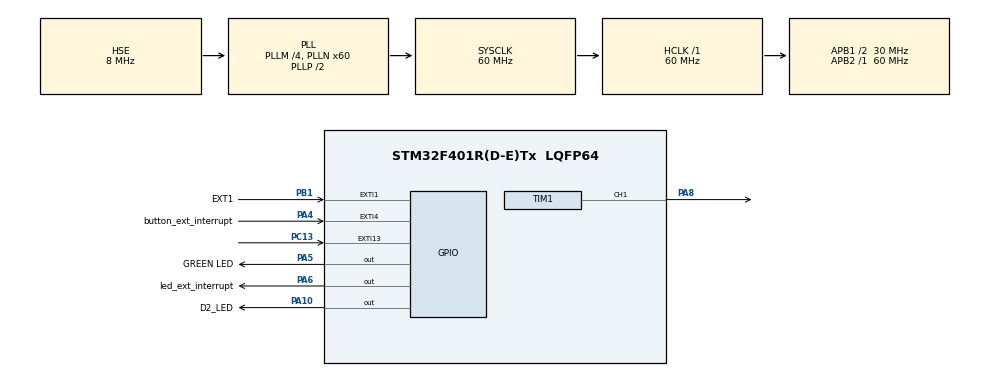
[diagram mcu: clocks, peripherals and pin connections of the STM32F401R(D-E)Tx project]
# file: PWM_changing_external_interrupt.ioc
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Mcu.Family=STM32F4
Mcu.Name=STM32F401R(D-E)Tx
Mcu.Package=LQFP64
NVIC.EXTI15_10_IRQn=true\:0\:0\:true\:false\:true\:true\:true\:true
NVIC.EXTI1_IRQn=true\:0\:0\:false\:false\:true\:true\:true\:true
NVIC.EXTI4_IRQn=true\:1\:0\:true\:false\:true\:true\:true\:true
NVIC.PriorityGroup=NVIC_PRIORITYGROUP_4
PA10.GPIO_Label=D2_LED
PA10.Signal=GPIO_Output
PA13.Mode=Serial_Wire
PA13.Signal=SYS_JTMS-SWDIO
PA14.Mode=Serial_Wire
PA14.Signal=SYS_JTCK-SWCLK
PA4.GPIO_Label=button_ext_interrupt
PA4.GPIO_ModeDefaultEXTI=GPIO_MODE_IT_FALLING
PA4.Signal=GPXTI4
PA5.GPIO_Label=GREEN LED
PA5.Signal=GPIO_Output
PA6.GPIO_Label=led_ext_interrupt
PA6.Signal=GPIO_Output
PA8.Signal=S_TIM1_CH1
PB1.GPIO_Label=EXT1
PB1.Signal=GPXTI1
PC13-ANTI_TAMP.Signal=GPXTI13
PH0\ -\ OSC_IN.Mode=HSE-External-Oscillator
PH0\ -\ OSC_IN.Signal=RCC_OSC_IN
PH1\ -\ OSC_OUT.Mode=HSE-External-Oscillator
PH1\ -\ OSC_OUT.Signal=RCC_OSC_OUT
ProjectManager.HeapSize=0x200
ProjectManager.StackSize=0x400
ProjectManager.TargetToolchain=STM32CubeIDE
RCC.48MHZClocksFreq_Value=30000000
RCC.AHBFreq_Value=60000000
RCC.APB1CLKDivider=RCC_HCLK_DIV2
RCC.APB1Freq_Value=30000000
RCC.APB1TimFreq_Value=60000000
RCC.APB2Freq_Value=60000000
RCC.APB2TimFreq_Value=60000000
RCC.CortexFreq_Value=60000000
RCC.HCLKFreq_Value=60000000
RCC.HSE_VALUE=8000000
RCC.HSI_VALUE=16000000
RCC.LSE_VALUE=32768
RCC.PLLM=4
RCC.PLLN=60
RCC.PLLSourceVirtual=RCC_PLLSOURCE_HSE
RCC.SYSCLKFreq_VALUE=60000000
RCC.SYSCLKSource=RCC_SYSCLKSOURCE_PLLCLK
RCC.VCOOutputFreq_Value=120000000
SH.S_TIM1_CH1.0=TIM1_CH1,PWM Generation1 CH1
TIM1.Channel-PWM\ Generation1\ CH1=TIM_CHANNEL_1
TIM1.Period=100-1
TIM1.Prescaler=80-1
VP_TIM1_VS_ClockSourceINT.Mode=Internal
board=custom

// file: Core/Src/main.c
/* USER CODE BEGIN Header */
/**
  ******************************************************************************
  * @file           : main.c
  * @brief          : Main program body
  ******************************************************************************
  * @attention
  *
  * Copyright (c) 2023 STMicroelectronics.
  * All rights reserved.
  *
  * This software is licensed under terms that can be found in the LICENSE file
  * in the root directory of this software component.
  * If no LICENSE file comes with this software, it is provided AS-IS.
  *
  ******************************************************************************
  */
/* USER CODE END Header */
#include "main.h"

TIM_HandleTypeDef htim1;

/* USER CODE BEGIN PV */
uint8_t Duty_cycle = 10;
uint8_t MODE = 0;

/* USER CODE END PV */

void SystemClock_Config(void);
static void MX_GPIO_Init(void);
static void MX_TIM1_Init(void);

/* USER CODE BEGIN 0 */
void HAL_GPIO_EXTI_Callback(uint16_t GPIO_Pin)
{

/*
	  MODE = MODE + 1;
	  HAL_GPIO_WritePin(led_ext_interrupt_GPIO_Port, led_ext_interrupt_Pin, GPIO_PIN_SET);
	  __NOP();
	  __NOP();
	  __NOP();
	  __NOP();
	  HAL_Delay(10);

	  HAL_GPIO_WritePin(led_ext_interrupt_GPIO_Port, led_ext_interrupt_Pin, GPIO_PIN_RESET);
	  Duty_cycle = Duty_cycle +10;

	  if(MODE > 3){
		  MODE = 0;
		  HAL_GPIO_WritePin(GREEN_LED_GPIO_Port, GREEN_LED_Pin, GPIO_PIN_SET);
	  }
*/
	if(GPIO_Pin == GPIO_PIN_13)
	{
	   HAL_GPIO_TogglePin(D2_LED_GPIO_Port, D2_LED_Pin);
	   HAL_GPIO_TogglePin(GREEN_LED_GPIO_Port, GREEN_LED_Pin);
	   Duty_cycle = Duty_cycle - 1;

	}

	if( GPIO_Pin == button_ext_interrupt_Pin)
	{
		HAL_GPIO_TogglePin(led_ext_interrupt_GPIO_Port, led_ext_interrupt_Pin);
		Duty_cycle = Duty_cycle + 10;

		if (Duty_cycle > 90)
		{
			Duty_cycle  = 0;
		}

	}
}
/* USER CODE END 0 */

int main(void)
{

  /* MCU Configuration--------------------------------------------------------*/

  /* Reset of all peripherals, Initializes the Flash interface and the Systick. */
  HAL_Init();

  /* Configure the system clock */
  SystemClock_Config();

  /* Initialize all configured peripherals */
  MX_GPIO_Init();
  MX_TIM1_Init();

  /* Infinite loop */
  while (1)
  {
	  TIM1 -> CCR1 = Duty_cycle;
	  HAL_TIM_PWM_Start(&htim1, TIM_CHANNEL_1);
  }
}

void SystemClock_Config(void)
{
  RCC_OscInitTypeDef RCC_OscInitStruct = {0};
  RCC_ClkInitTypeDef RCC_ClkInitStruct = {0};

  /** Configure the main internal regulator output voltage
  */
  __HAL_RCC_PWR_CLK_ENABLE();
  __HAL_PWR_VOLTAGESCALING_CONFIG(PWR_REGULATOR_VOLTAGE_SCALE2);

  /** Initializes the RCC Oscillators according to the specified parameters
  * in the RCC_OscInitTypeDef structure.
  */
  RCC_OscInitStruct.OscillatorType = RCC_OSCILLATORTYPE_HSE;
  RCC_OscInitStruct.HSEState = RCC_HSE_ON;
  RCC_OscInitStruct.PLL.PLLState = RCC_PLL_ON;
  RCC_OscInitStruct.PLL.PLLSource = RCC_PLLSOURCE_HSE;
  RCC_OscInitStruct.PLL.PLLM = 4;
  RCC_OscInitStruct.PLL.PLLN = 60;
  RCC_OscInitStruct.PLL.PLLP = RCC_PLLP_DIV2;
  RCC_OscInitStruct.PLL.PLLQ = 4;
  if (HAL_RCC_OscConfig(&RCC_OscInitStruct) != HAL_OK)
  {
    Error_Handler();
  }

  /** Initializes the CPU, AHB and APB buses clocks
  */
  RCC_ClkInitStruct.ClockType = RCC_CLOCKTYPE_HCLK|RCC_CLOCKTYPE_SYSCLK
                              |RCC_CLOCKTYPE_PCLK1|RCC_CLOCKTYPE_PCLK2;
  RCC_ClkInitStruct.SYSCLKSource = RCC_SYSCLKSOURCE_PLLCLK;
  RCC_ClkInitStruct.AHBCLKDivider = RCC_SYSCLK_DIV1;
  RCC_ClkInitStruct.APB1CLKDivider = RCC_HCLK_DIV2;
  RCC_ClkInitStruct.APB2CLKDivider = RCC_HCLK_DIV1;

  if (HAL_RCC_ClockConfig(&RCC_ClkInitStruct, FLASH_LATENCY_1) != HAL_OK)
  {
    Error_Handler();
  }
}

static void MX_TIM1_Init(void)
{

  TIM_ClockConfigTypeDef sClockSourceConfig = {0};
  TIM_MasterConfigTypeDef sMasterConfig = {0};
  TIM_OC_InitTypeDef sConfigOC = {0};
  TIM_BreakDeadTimeConfigTypeDef sBreakDeadTimeConfig = {0};

  htim1.Instance = TIM1;
  htim1.Init.Prescaler = 80-1;
  htim1.Init.CounterMode = TIM_COUNTERMODE_UP;
  htim1.Init.Period = 100-1;
  htim1.Init.ClockDivision = TIM_CLOCKDIVISION_DIV1;
  htim1.Init.RepetitionCounter = 0;
  htim1.Init.AutoReloadPreload = TIM_AUTORELOAD_PRELOAD_DISABLE;
  if (HAL_TIM_Base_Init(&htim1) != HAL_OK)
  {
    Error_Handler();
  }
  sClockSourceConfig.ClockSource = TIM_CLOCKSOURCE_INTERNAL;
  if (HAL_TIM_ConfigClockSource(&htim1, &sClockSourceConfig) != HAL_OK)
  {
    Error_Handler();
  }
  if (HAL_TIM_PWM_Init(&htim1) != HAL_OK)
  {
    Error_Handler();
  }
  sMasterConfig.MasterOutputTrigger = TIM_TRGO_RESET;
  sMasterConfig.MasterSlaveMode = TIM_MASTERSLAVEMODE_DISABLE;
  if (HAL_TIMEx_MasterConfigSynchronization(&htim1, &sMasterConfig) != HAL_OK)
  {
    Error_Handler();
  }
  sConfigOC.OCMode = TIM_OCMODE_PWM1;
  sConfigOC.Pulse = 0;
  sConfigOC.OCPolarity = TIM_OCPOLARITY_HIGH;
  sConfigOC.OCNPolarity = TIM_OCNPOLARITY_HIGH;
  sConfigOC.OCFastMode = TIM_OCFAST_DISABLE;
  sConfigOC.OCIdleState = TIM_OCIDLESTATE_RESET;
  sConfigOC.OCNIdleState = TIM_OCNIDLESTATE_RESET;
  if (HAL_TIM_PWM_ConfigChannel(&htim1, &sConfigOC, TIM_CHANNEL_1) != HAL_OK)
  {
    Error_Handler();
  }
  sBreakDeadTimeConfig.OffStateRunMode = TIM_OSSR_DISABLE;
  sBreakDeadTimeConfig.OffStateIDLEMode = TIM_OSSI_DISABLE;
  sBreakDeadTimeConfig.LockLevel = TIM_LOCKLEVEL_OFF;
  sBreakDeadTimeConfig.DeadTime = 0;
  sBreakDeadTimeConfig.BreakState = TIM_BREAK_DISABLE;
  sBreakDeadTimeConfig.BreakPolarity = TIM_BREAKPOLARITY_HIGH;
  sBreakDeadTimeConfig.AutomaticOutput = TIM_AUTOMATICOUTPUT_DISABLE;
  if (HAL_TIMEx_ConfigBreakDeadTime(&htim1, &sBreakDeadTimeConfig) != HAL_OK)
  {
    Error_Handler();
  }
  HAL_TIM_MspPostInit(&htim1);

}

static void MX_GPIO_Init(void)
{
  GPIO_InitTypeDef GPIO_InitStruct = {0};

  /* GPIO Ports Clock Enable */
  __HAL_RCC_GPIOC_CLK_ENABLE();
  __HAL_RCC_GPIOH_CLK_ENABLE();
  __HAL_RCC_GPIOA_CLK_ENABLE();
  __HAL_RCC_GPIOB_CLK_ENABLE();

  /*Configure GPIO pin Output Level */
  HAL_GPIO_WritePin(GPIOA, GREEN_LED_Pin|led_ext_interrupt_Pin|D2_LED_Pin, GPIO_PIN_RESET);

  /*Configure GPIO pin : PC13 */
  GPIO_InitStruct.Pin = GPIO_PIN_13;
  GPIO_InitStruct.Mode = GPIO_MODE_IT_RISING;
  GPIO_InitStruct.Pull = GPIO_NOPULL;
  HAL_GPIO_Init(GPIOC, &GPIO_InitStruct);

  /*Configure GPIO pin : button_ext_interrupt_Pin */
  GPIO_InitStruct.Pin = button_ext_interrupt_Pin;
  GPIO_InitStruct.Mode = GPIO_MODE_IT_FALLING;
  GPIO_InitStruct.Pull = GPIO_NOPULL;
  HAL_GPIO_Init(button_ext_interrupt_GPIO_Port, &GPIO_InitStruct);

  /*Configure GPIO pins : GREEN_LED_Pin led_ext_interrupt_Pin D2_LED_Pin */
  GPIO_InitStruct.Pin = GREEN_LED_Pin|led_ext_interrupt_Pin|D2_LED_Pin;
  GPIO_InitStruct.Mode = GPIO_MODE_OUTPUT_PP;
  GPIO_InitStruct.Pull = GPIO_NOPULL;
  GPIO_InitStruct.Speed = GPIO_SPEED_FREQ_LOW;
  HAL_GPIO_Init(GPIOA, &GPIO_InitStruct);

  /*Configure GPIO pin : EXT1_Pin */
  GPIO_InitStruct.Pin = EXT1_Pin;
  GPIO_InitStruct.Mode = GPIO_MODE_IT_RISING;
  GPIO_InitStruct.Pull = GPIO_NOPULL;
  HAL_GPIO_Init(EXT1_GPIO_Port, &GPIO_InitStruct);

  /* EXTI interrupt init*/
  HAL_NVIC_SetPriority(EXTI1_IRQn, 0, 0);
  HAL_NVIC_EnableIRQ(EXTI1_IRQn);

  HAL_NVIC_SetPriority(EXTI4_IRQn, 1, 0);
  HAL_NVIC_EnableIRQ(EXTI4_IRQn);

  HAL_NVIC_SetPriority(EXTI15_10_IRQn, 0, 0);
  HAL_NVIC_EnableIRQ(EXTI15_10_IRQn);

}

void Error_Handler(void)
{
  __disable_irq();
  while (1)
  {
  }
}
